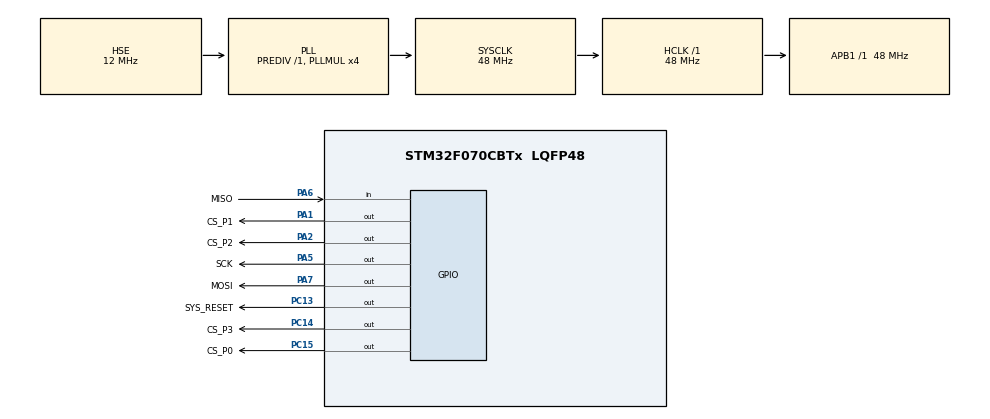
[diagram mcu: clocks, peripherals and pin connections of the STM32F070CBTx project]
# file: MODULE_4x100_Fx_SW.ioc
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Mcu.Family=STM32F0
RCC.PLLSourceVirtual=RCC_PLLSOURCE_HSE
PC13.Signal=GPIO_Output
PA2.GPIO_Speed=GPIO_SPEED_FREQ_HIGH
PA7.GPIO_ModeDefaultOutputPP=GPIO_MODE_OUTPUT_OD
PA6.GPIO_Label=MISO
PC13.GPIO_Label=SYS_RESET
PC14-OSC32_IN.Signal=GPIO_Output
PC15-OSC32_OUT.GPIO_Label=CS_P0
RCC.SYSCLKSource=RCC_SYSCLKSOURCE_PLLCLK
ProjectManager.StackSize=0x400
PA13.Signal=SYS_SWDIO
PA7.PinState=GPIO_PIN_SET
ProjectManager.TargetToolchain=EWARM V8.32
PC13.GPIO_ModeDefaultOutputPP=GPIO_MODE_OUTPUT_OD
RCC.HCLKFreq_Value=48000000
PC15-OSC32_OUT.Signal=GPIO_Output
PA1.Signal=GPIO_Output
RCC.AHBFreq_Value=48000000
PF0-OSC_IN.Mode=HSE-External-Oscillator
PA5.Signal=GPIO_Output
RCC.HSE_VALUE=12000000
board=custom
RCC.PLLMUL=RCC_PLL_MUL4
PA7.GPIO_Speed=GPIO_SPEED_FREQ_HIGH
PA2.PinState=GPIO_PIN_SET
PA14.Mode=Serial_Wire
PA1.GPIO_Speed=GPIO_SPEED_FREQ_HIGH
PA1.GPIO_Label=CS_P1
PC15-OSC32_OUT.PinState=GPIO_PIN_SET
PA13.Mode=Serial_Wire
Mcu.Name=STM32F070CBTx
PA2.Signal=GPIO_Output
RCC.SYSCLKFreq_VALUE=48000000
Mcu.Package=LQFP48
PA6.Signal=GPIO_Input
PA7.GPIO_Label=MOSI
PA2.GPIO_ModeDefaultOutputPP=GPIO_MODE_OUTPUT_OD
PA5.GPIO_Label=SCK
PC14-OSC32_IN.PinState=GPIO_PIN_SET
PA2.GPIO_Label=CS_P2
PA14.Signal=SYS_SWCLK
ProjectManager.HeapSize=0x200
PA1.PinState=GPIO_PIN_SET
PA5.GPIO_Speed=GPIO_SPEED_FREQ_HIGH
PC15-OSC32_OUT.GPIO_ModeDefaultOutputPP=GPIO_MODE_OUTPUT_OD
PC14-OSC32_IN.GPIO_ModeDefaultOutputPP=GPIO_MODE_OUTPUT_OD
RCC.APB1TimFreq_Value=48000000
PC14-OSC32_IN.GPIO_Label=CS_P3
PF0-OSC_IN.Signal=RCC_OSC_IN
PF1-OSC_OUT.Mode=HSE-External-Oscillator
RCC.APB1Freq_Value=48000000
PF1-OSC_OUT.Signal=RCC_OSC_OUT
PC13.PinState=GPIO_PIN_RESET
PA7.Signal=GPIO_Output
PA1.GPIO_ModeDefaultOutputPP=GPIO_MODE_OUTPUT_OD

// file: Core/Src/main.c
/* USER CODE BEGIN Header */
/**
  ******************************************************************************
  * @file           : main.c
  * @brief          : Main program body
  ******************************************************************************
  * @attention
  *
  * <h2><center>&copy; Copyright (c) 2021 STMicroelectronics.
  * All rights reserved.</center></h2>
  *
  * This software component is licensed by ST under BSD 3-Clause license,
  * the "License"; You may not use this file except in compliance with the
  * License. You may obtain a copy of the License at:
  *                        opensource.org/licenses/BSD-3-Clause
  *
  ******************************************************************************
  */
/* USER CODE END Header */
#include "main.h"
#include "gpio.h"

/* USER CODE BEGIN Includes */
#include "def.h"
/* USER CODE END Includes */

void SystemClock_Config(void);

int main(void)
{

  /* MCU Configuration--------------------------------------------------------*/

  /* Reset of all peripherals, Initializes the Flash interface and the Systick. */
  HAL_Init();

  /* Configure the system clock */
  SystemClock_Config();

  /* Initialize all configured peripherals */
  MX_GPIO_Init();
  /* USER CODE BEGIN 2 */
  	HAL_Delay(20);	// delay 20 ms for the HW reset (SYS_RESET)
	SYS_RESET_H
  /* USER CODE END 2 */

  /* Infinite loop */
  while (1)
  {

  }
}

void SystemClock_Config(void)
{
  RCC_OscInitTypeDef RCC_OscInitStruct = {0};
  RCC_ClkInitTypeDef RCC_ClkInitStruct = {0};

  /** Initializes the RCC Oscillators according to the specified parameters
  * in the RCC_OscInitTypeDef structure.
  */
  RCC_OscInitStruct.OscillatorType = RCC_OSCILLATORTYPE_HSE;
  RCC_OscInitStruct.HSEState = RCC_HSE_ON;
  RCC_OscInitStruct.PLL.PLLState = RCC_PLL_ON;
  RCC_OscInitStruct.PLL.PLLSource = RCC_PLLSOURCE_HSE;
  RCC_OscInitStruct.PLL.PLLMUL = RCC_PLL_MUL4;
  RCC_OscInitStruct.PLL.PREDIV = RCC_PREDIV_DIV1;
  if (HAL_RCC_OscConfig(&RCC_OscInitStruct) != HAL_OK)
  {
    Error_Handler();
  }
  /** Initializes the CPU, AHB and APB buses clocks
  */
  RCC_ClkInitStruct.ClockType = RCC_CLOCKTYPE_HCLK|RCC_CLOCKTYPE_SYSCLK
                              |RCC_CLOCKTYPE_PCLK1;
  RCC_ClkInitStruct.SYSCLKSource = RCC_SYSCLKSOURCE_PLLCLK;
  RCC_ClkInitStruct.AHBCLKDivider = RCC_SYSCLK_DIV1;
  RCC_ClkInitStruct.APB1CLKDivider = RCC_HCLK_DIV1;

  if (HAL_RCC_ClockConfig(&RCC_ClkInitStruct, FLASH_LATENCY_1) != HAL_OK)
  {
    Error_Handler();
  }
}

void Error_Handler(void)
{
  __disable_irq();
  while (1)
  {
  }
}

/************************ (C) COPYRIGHT STMicroelectronics *****END OF FILE****/
